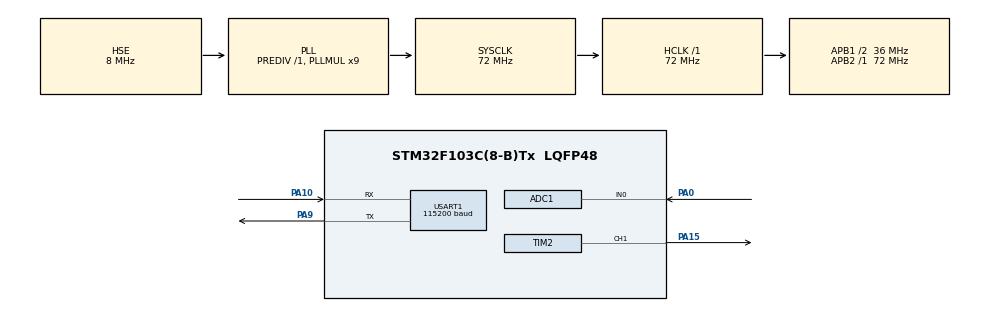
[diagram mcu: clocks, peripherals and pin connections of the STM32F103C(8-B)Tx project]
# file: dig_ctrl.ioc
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ADC1.Channel-102\#ChannelRegularConversion=ADC_CHANNEL_0
ADC1.ExternalTrigConv=ADC_EXTERNALTRIGCONV_T2_CC2
ADC1.NbrOfConversionFlag=1
ADC1.Rank-102\#ChannelRegularConversion=1
ADC1.SamplingTime-102\#ChannelRegularConversion=ADC_SAMPLETIME_1CYCLE_5
ADC1.master=1
Dma.Request0=USART1_RX
Dma.USART1_RX.0.Direction=DMA_PERIPH_TO_MEMORY
Dma.USART1_RX.0.Instance=DMA1_Channel5
Dma.USART1_RX.0.MemDataAlignment=DMA_MDATAALIGN_BYTE
Dma.USART1_RX.0.MemInc=DMA_MINC_ENABLE
Dma.USART1_RX.0.Mode=DMA_CIRCULAR
Dma.USART1_RX.0.PeriphDataAlignment=DMA_PDATAALIGN_BYTE
Dma.USART1_RX.0.PeriphInc=DMA_PINC_DISABLE
Dma.USART1_RX.0.Priority=DMA_PRIORITY_LOW
Mcu.Family=STM32F1
Mcu.Name=STM32F103C(8-B)Tx
Mcu.Package=LQFP48
NVIC.ADC1_2_IRQn=true\:0\:0\:false\:false\:true\:true
NVIC.DMA1_Channel5_IRQn=true\:0\:0\:false\:false\:true\:false
NVIC.PriorityGroup=NVIC_PRIORITYGROUP_4
NVIC.USART1_IRQn=true\:0\:0\:false\:false\:true\:true
PA0-WKUP.Signal=ADCx_IN0
PA10.Mode=Asynchronous
PA10.Signal=USART1_RX
PA13.Mode=Serial_Wire
PA13.Signal=SYS_JTMS-SWDIO
PA14.Mode=Serial_Wire
PA14.Signal=SYS_JTCK-SWCLK
PA15.Signal=S_TIM2_CH1_ETR
PA9.Mode=Asynchronous
PA9.Signal=USART1_TX
PD0-OSC_IN.Mode=HSE-External-Oscillator
PD0-OSC_IN.Signal=RCC_OSC_IN
PD1-OSC_OUT.Mode=HSE-External-Oscillator
PD1-OSC_OUT.Signal=RCC_OSC_OUT
ProjectManager.HeapSize=0x200
ProjectManager.StackSize=0x400
ProjectManager.TargetToolchain=SW4STM32
RCC.ADCPresc=RCC_ADCPCLK2_DIV6
RCC.AHBFreq_Value=72000000
RCC.APB1CLKDivider=RCC_HCLK_DIV2
RCC.APB1Freq_Value=36000000
RCC.APB1TimFreq_Value=72000000
RCC.APB2Freq_Value=72000000
RCC.APB2TimFreq_Value=72000000
RCC.HCLKFreq_Value=72000000
RCC.PLLMUL=RCC_PLL_MUL9
RCC.PLLSourceVirtual=RCC_PLLSOURCE_HSE
RCC.SYSCLKFreq_VALUE=72000000
RCC.SYSCLKSource=RCC_SYSCLKSOURCE_PLLCLK
RCC.USBFreq_Value=72000000
SH.ADCx_IN0.0=ADC1_IN0,IN0
SH.S_TIM2_CH1_ETR.0=TIM2_CH1,PWM Generation1 CH1
TIM2.AutoReloadPreload=TIM_AUTORELOAD_PRELOAD_DISABLE
TIM2.Channel-Output\ Compare2\ No\ Output=TIM_CHANNEL_2
TIM2.Channel-PWM\ Generation1\ CH1=TIM_CHANNEL_1
TIM2.CounterMode=TIM_COUNTERMODE_CENTERALIGNED1
TIM2.OCFastMode_PWM-PWM\ Generation1\ CH1=TIM_OCFAST_ENABLE
TIM2.Period=1800
TIM2.Prescaler=0
TIM2.Pulse-PWM\ Generation1\ CH1=450
USART1.BaudRate=115200
USART1.VirtualMode=VM_ASYNC
VP_TIM2_VS_ClockSourceINT.Mode=Internal
VP_TIM2_VS_no_output2.Mode=Output Compare2 No Output
board=dig_ctrl

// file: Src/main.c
/**
  ******************************************************************************
  * @file           : main.c
  * @brief          : Main program body
  ******************************************************************************
  ** This notice applies to any and all portions of this file
  * that are not between comment pairs USER CODE BEGIN and
  * USER CODE END. Other portions of this file, whether
  * inserted by the user or by software development tools
  * are owned by their respective copyright owners.
  *
  * COPYRIGHT(c) 2018 STMicroelectronics
  *
  * Redistribution and use in source and binary forms, with or without modification,
  * are permitted provided that the following conditions are met:
  *   1. Redistributions of source code must retain the above copyright notice,
  *      this list of conditions and the following disclaimer.
  *   2. Redistributions in binary form must reproduce the above copyright notice,
  *      this list of conditions and the following disclaimer in the documentation
  *      and/or other materials provided with the distribution.
  *   3. Neither the name of STMicroelectronics nor the names of its contributors
  *      may be used to endorse or promote products derived from this software
  *      without specific prior written permission.
  *
  * THIS SOFTWARE IS PROVIDED BY THE COPYRIGHT HOLDERS AND CONTRIBUTORS "AS IS"
  * AND ANY EXPRESS OR IMPLIED WARRANTIES, INCLUDING, BUT NOT LIMITED TO, THE
  * IMPLIED WARRANTIES OF MERCHANTABILITY AND FITNESS FOR A PARTICULAR PURPOSE ARE
  * DISCLAIMED. IN NO EVENT SHALL THE COPYRIGHT HOLDER OR CONTRIBUTORS BE LIABLE
  * FOR ANY DIRECT, INDIRECT, INCIDENTAL, SPECIAL, EXEMPLARY, OR CONSEQUENTIAL
  * DAMAGES (INCLUDING, BUT NOT LIMITED TO, PROCUREMENT OF SUBSTITUTE GOODS OR
  * SERVICES; LOSS OF USE, DATA, OR PROFITS; OR BUSINESS INTERRUPTION) HOWEVER
  * CAUSED AND ON ANY THEORY OF LIABILITY, WHETHER IN CONTRACT, STRICT LIABILITY,
  * OR TORT (INCLUDING NEGLIGENCE OR OTHERWISE) ARISING IN ANY WAY OUT OF THE USE
  * OF THIS SOFTWARE, EVEN IF ADVISED OF THE POSSIBILITY OF SUCH DAMAGE.
  *
  ******************************************************************************
  */
#include "main.h"
#include "stm32f1xx_hal.h"
#include "console.h"

ADC_HandleTypeDef hadc1;

TIM_HandleTypeDef htim2;

UART_HandleTypeDef huart1;
DMA_HandleTypeDef hdma_usart1_rx;

/* USER CODE BEGIN PV */
/* Private variables ---------------------------------------------------------*/

/* USER CODE END PV */

void SystemClock_Config(void);
static void MX_GPIO_Init(void);
static void MX_DMA_Init(void);
static void MX_USART1_UART_Init(void);
static void MX_ADC1_Init(void);
static void MX_TIM2_Init(void);

void HAL_TIM_MspPostInit(TIM_HandleTypeDef *htim);

/* USER CODE BEGIN PFP */
/* Private function prototypes -----------------------------------------------*/

/* USER CODE END PFP */

int main(void)
{

  /* MCU Configuration----------------------------------------------------------*/

  /* Reset of all peripherals, Initializes the Flash interface and the Systick. */
  HAL_Init();

  /* Configure the system clock */
  SystemClock_Config();

  /* Initialize all configured peripherals */
  MX_GPIO_Init();
  MX_DMA_Init();
  MX_USART1_UART_Init();
  MX_ADC1_Init();
  MX_TIM2_Init();
  /* USER CODE BEGIN 2 */

  CONSOLE_INIT(&huart1);

   HAL_TIM_PWM_Start(&htim2,TIM_CHANNEL_1);
   HAL_TIM_PWM_Start(&htim2,TIM_CHANNEL_2);
  /* USER CODE END 2 */

  /* Infinite loop */
  /* USER CODE BEGIN WHILE */
  while (1)
  {
  if(ConsolePollBuffer())
	  ConsoleParseBuffer();

  /* USER CODE END WHILE */

  }

}

void SystemClock_Config(void)
{

  RCC_OscInitTypeDef RCC_OscInitStruct;
  RCC_ClkInitTypeDef RCC_ClkInitStruct;
  RCC_PeriphCLKInitTypeDef PeriphClkInit;

    /**Initializes the CPU, AHB and APB busses clocks
    */
  RCC_OscInitStruct.OscillatorType = RCC_OSCILLATORTYPE_HSE;
  RCC_OscInitStruct.HSEState = RCC_HSE_ON;
  RCC_OscInitStruct.HSEPredivValue = RCC_HSE_PREDIV_DIV1;
  RCC_OscInitStruct.HSIState = RCC_HSI_ON;
  RCC_OscInitStruct.PLL.PLLState = RCC_PLL_ON;
  RCC_OscInitStruct.PLL.PLLSource = RCC_PLLSOURCE_HSE;
  RCC_OscInitStruct.PLL.PLLMUL = RCC_PLL_MUL9;
  if (HAL_RCC_OscConfig(&RCC_OscInitStruct) != HAL_OK)
  {
    _Error_Handler(__FILE__, __LINE__);
  }

    /**Initializes the CPU, AHB and APB busses clocks
    */
  RCC_ClkInitStruct.ClockType = RCC_CLOCKTYPE_HCLK|RCC_CLOCKTYPE_SYSCLK
                              |RCC_CLOCKTYPE_PCLK1|RCC_CLOCKTYPE_PCLK2;
  RCC_ClkInitStruct.SYSCLKSource = RCC_SYSCLKSOURCE_PLLCLK;
  RCC_ClkInitStruct.AHBCLKDivider = RCC_SYSCLK_DIV1;
  RCC_ClkInitStruct.APB1CLKDivider = RCC_HCLK_DIV2;
  RCC_ClkInitStruct.APB2CLKDivider = RCC_HCLK_DIV1;

  if (HAL_RCC_ClockConfig(&RCC_ClkInitStruct, FLASH_LATENCY_2) != HAL_OK)
  {
    _Error_Handler(__FILE__, __LINE__);
  }

  PeriphClkInit.PeriphClockSelection = RCC_PERIPHCLK_ADC;
  PeriphClkInit.AdcClockSelection = RCC_ADCPCLK2_DIV6;
  if (HAL_RCCEx_PeriphCLKConfig(&PeriphClkInit) != HAL_OK)
  {
    _Error_Handler(__FILE__, __LINE__);
  }

    /**Configure the Systick interrupt time
    */
  HAL_SYSTICK_Config(HAL_RCC_GetHCLKFreq()/1000);

    /**Configure the Systick
    */
  HAL_SYSTICK_CLKSourceConfig(SYSTICK_CLKSOURCE_HCLK);

  /* SysTick_IRQn interrupt configuration */
  HAL_NVIC_SetPriority(SysTick_IRQn, 0, 0);
}

/* ADC1 init function */
static void MX_ADC1_Init(void)
{

  ADC_ChannelConfTypeDef sConfig;

    /**Common config
    */
  hadc1.Instance = ADC1;
  hadc1.Init.ScanConvMode = ADC_SCAN_DISABLE;
  hadc1.Init.ContinuousConvMode = DISABLE;
  hadc1.Init.DiscontinuousConvMode = DISABLE;
  hadc1.Init.ExternalTrigConv = ADC_EXTERNALTRIGCONV_T2_CC2;
  hadc1.Init.DataAlign = ADC_DATAALIGN_RIGHT;
  hadc1.Init.NbrOfConversion = 1;
  if (HAL_ADC_Init(&hadc1) != HAL_OK)
  {
    _Error_Handler(__FILE__, __LINE__);
  }

    /**Configure Regular Channel
    */
  sConfig.Channel = ADC_CHANNEL_0;
  sConfig.Rank = ADC_REGULAR_RANK_1;
  sConfig.SamplingTime = ADC_SAMPLETIME_1CYCLE_5;
  if (HAL_ADC_ConfigChannel(&hadc1, &sConfig) != HAL_OK)
  {
    _Error_Handler(__FILE__, __LINE__);
  }

}

/* TIM2 init function */
static void MX_TIM2_Init(void)
{

  TIM_ClockConfigTypeDef sClockSourceConfig;
  TIM_MasterConfigTypeDef sMasterConfig;
  TIM_OC_InitTypeDef sConfigOC;

  htim2.Instance = TIM2;
  htim2.Init.Prescaler = 0;
  htim2.Init.CounterMode = TIM_COUNTERMODE_CENTERALIGNED1;
  htim2.Init.Period = 1800;
  htim2.Init.ClockDivision = TIM_CLOCKDIVISION_DIV1;
  htim2.Init.AutoReloadPreload = TIM_AUTORELOAD_PRELOAD_DISABLE;
  if (HAL_TIM_Base_Init(&htim2) != HAL_OK)
  {
    _Error_Handler(__FILE__, __LINE__);
  }

  sClockSourceConfig.ClockSource = TIM_CLOCKSOURCE_INTERNAL;
  if (HAL_TIM_ConfigClockSource(&htim2, &sClockSourceConfig) != HAL_OK)
  {
    _Error_Handler(__FILE__, __LINE__);
  }

  if (HAL_TIM_PWM_Init(&htim2) != HAL_OK)
  {
    _Error_Handler(__FILE__, __LINE__);
  }

  if (HAL_TIM_OC_Init(&htim2) != HAL_OK)
  {
    _Error_Handler(__FILE__, __LINE__);
  }

  sMasterConfig.MasterOutputTrigger = TIM_TRGO_RESET;
  sMasterConfig.MasterSlaveMode = TIM_MASTERSLAVEMODE_DISABLE;
  if (HAL_TIMEx_MasterConfigSynchronization(&htim2, &sMasterConfig) != HAL_OK)
  {
    _Error_Handler(__FILE__, __LINE__);
  }

  sConfigOC.OCMode = TIM_OCMODE_PWM1;
  sConfigOC.Pulse = 450;
  sConfigOC.OCPolarity = TIM_OCPOLARITY_HIGH;
  sConfigOC.OCFastMode = TIM_OCFAST_ENABLE;
  if (HAL_TIM_PWM_ConfigChannel(&htim2, &sConfigOC, TIM_CHANNEL_1) != HAL_OK)
  {
    _Error_Handler(__FILE__, __LINE__);
  }

  sConfigOC.OCMode = TIM_OCMODE_TIMING;
  sConfigOC.Pulse = 0;
  sConfigOC.OCFastMode = TIM_OCFAST_DISABLE;
  if (HAL_TIM_OC_ConfigChannel(&htim2, &sConfigOC, TIM_CHANNEL_2) != HAL_OK)
  {
    _Error_Handler(__FILE__, __LINE__);
  }

  HAL_TIM_MspPostInit(&htim2);

}

/* USART1 init function */
static void MX_USART1_UART_Init(void)
{

  huart1.Instance = USART1;
  huart1.Init.BaudRate = 115200;
  huart1.Init.WordLength = UART_WORDLENGTH_8B;
  huart1.Init.StopBits = UART_STOPBITS_1;
  huart1.Init.Parity = UART_PARITY_NONE;
  huart1.Init.Mode = UART_MODE_TX_RX;
  huart1.Init.HwFlowCtl = UART_HWCONTROL_NONE;
  huart1.Init.OverSampling = UART_OVERSAMPLING_16;
  if (HAL_UART_Init(&huart1) != HAL_OK)
  {
    _Error_Handler(__FILE__, __LINE__);
  }

}

static void MX_DMA_Init(void)
{
  /* DMA controller clock enable */
  __HAL_RCC_DMA1_CLK_ENABLE();

  /* DMA interrupt init */
  /* DMA1_Channel5_IRQn interrupt configuration */
  HAL_NVIC_SetPriority(DMA1_Channel5_IRQn, 0, 0);
  HAL_NVIC_EnableIRQ(DMA1_Channel5_IRQn);

}

/** Configure pins as
        * Analog
        * Input
        * Output
        * EVENT_OUT
        * EXTI
*/
static void MX_GPIO_Init(void)
{

  /* GPIO Ports Clock Enable */
  __HAL_RCC_GPIOD_CLK_ENABLE();
  __HAL_RCC_GPIOA_CLK_ENABLE();

}

void _Error_Handler(char *file, int line)
{
  while(1)
  {
  }
}

/************************ (C) COPYRIGHT STMicroelectronics *****END OF FILE****/
